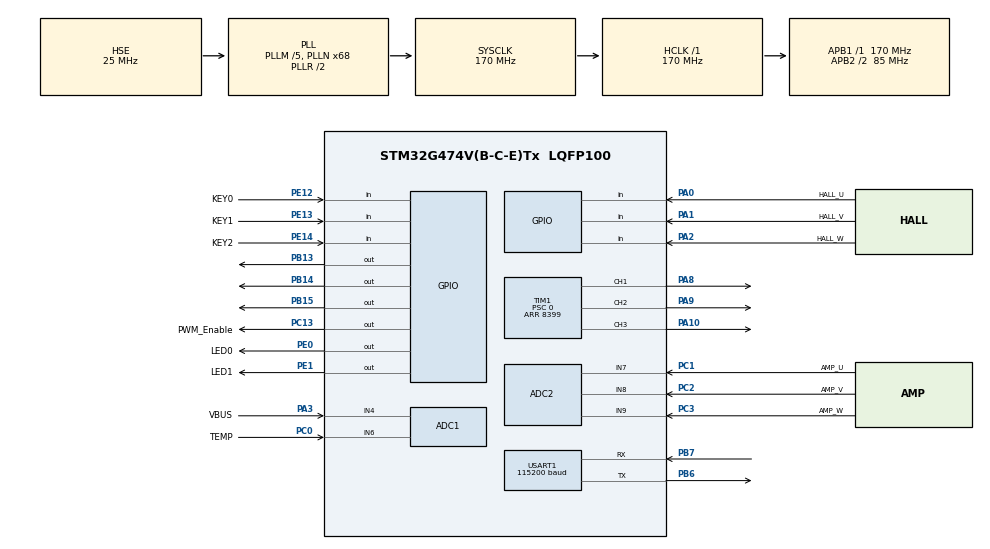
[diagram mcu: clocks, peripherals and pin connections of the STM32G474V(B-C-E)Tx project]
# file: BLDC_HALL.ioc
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ADC1.Channel-2\#ChannelRegularConversion=ADC_CHANNEL_4
ADC1.Channel-3\#ChannelRegularConversion=ADC_CHANNEL_6
ADC1.ContinuousConvMode=ENABLE
ADC1.DMAContinuousRequests=ENABLE
ADC1.EOCSelection=ADC_EOC_SINGLE_CONV
ADC1.EnableInjectedConversion=DISABLE
ADC1.LowPowerAutoWait=DISABLE
ADC1.Mode=ADC_MODE_INDEPENDENT
ADC1.NbrOfConversion=2
ADC1.NbrOfConversionFlag=1
ADC1.OffsetNumber-2\#ChannelRegularConversion=ADC_OFFSET_NONE
ADC1.OffsetNumber-3\#ChannelRegularConversion=ADC_OFFSET_NONE
ADC1.Rank-2\#ChannelRegularConversion=1
ADC1.Rank-3\#ChannelRegularConversion=2
ADC1.SamplingTime-2\#ChannelRegularConversion=ADC_SAMPLETIME_92CYCLES_5
ADC1.SamplingTime-3\#ChannelRegularConversion=ADC_SAMPLETIME_92CYCLES_5
ADC1.master=1
ADC2.EnableAnalogWatchDog1=false
ADC2.EnableInjectedConversion=ENABLE
ADC2.EnableRegularConversion=DISABLE
ADC2.ExternalTrigInjecConv=ADC_EXTERNALTRIGINJEC_T1_TRGO
ADC2.ExternalTrigInjecConvEdge=ADC_EXTERNALTRIGINJECCONV_EDGE_RISING
ADC2.InjNumberOfConversion=3
ADC2.InjectedChannel-1\#ChannelInjectedConversion=ADC_CHANNEL_7
ADC2.InjectedChannel-2\#ChannelInjectedConversion=ADC_CHANNEL_8
ADC2.InjectedChannel-3\#ChannelInjectedConversion=ADC_CHANNEL_9
ADC2.InjectedConvMode=None
ADC2.InjectedOffsetNumber-1\#ChannelInjectedConversion=ADC_OFFSET_NONE
ADC2.InjectedOffsetNumber-2\#ChannelInjectedConversion=ADC_OFFSET_NONE
ADC2.InjectedOffsetNumber-3\#ChannelInjectedConversion=ADC_OFFSET_NONE
ADC2.InjectedRank-1\#ChannelInjectedConversion=1
ADC2.InjectedRank-2\#ChannelInjectedConversion=2
ADC2.InjectedRank-3\#ChannelInjectedConversion=3
ADC2.InjectedSamplingTime-1\#ChannelInjectedConversion=ADC_SAMPLETIME_24CYCLES_5
ADC2.InjectedSamplingTime-2\#ChannelInjectedConversion=ADC_SAMPLETIME_24CYCLES_5
ADC2.InjectedSamplingTime-3\#ChannelInjectedConversion=ADC_SAMPLETIME_24CYCLES_5
Dma.ADC1.1.Direction=DMA_PERIPH_TO_MEMORY
Dma.ADC1.1.EventEnable=DISABLE
Dma.ADC1.1.Instance=DMA1_Channel2
Dma.ADC1.1.MemDataAlignment=DMA_MDATAALIGN_HALFWORD
Dma.ADC1.1.MemInc=DMA_MINC_ENABLE
Dma.ADC1.1.Mode=DMA_CIRCULAR
Dma.ADC1.1.PeriphDataAlignment=DMA_PDATAALIGN_HALFWORD
Dma.ADC1.1.PeriphInc=DMA_PINC_DISABLE
Dma.ADC1.1.Polarity=HAL_DMAMUX_REQ_GEN_RISING
Dma.ADC1.1.Priority=DMA_PRIORITY_LOW
Dma.ADC1.1.RequestNumber=1
Dma.ADC1.1.SignalID=NONE
Dma.ADC1.1.SyncEnable=DISABLE
Dma.ADC1.1.SyncPolarity=HAL_DMAMUX_SYNC_NO_EVENT
Dma.ADC1.1.SyncRequestNumber=1
Dma.ADC1.1.SyncSignalID=NONE
Dma.Request0=USART1_TX
Dma.Request1=ADC1
Dma.USART1_TX.0.Direction=DMA_MEMORY_TO_PERIPH
Dma.USART1_TX.0.EventEnable=DISABLE
Dma.USART1_TX.0.Instance=DMA1_Channel1
Dma.USART1_TX.0.MemDataAlignment=DMA_MDATAALIGN_BYTE
Dma.USART1_TX.0.MemInc=DMA_MINC_ENABLE
Dma.USART1_TX.0.Mode=DMA_NORMAL
Dma.USART1_TX.0.PeriphDataAlignment=DMA_PDATAALIGN_BYTE
Dma.USART1_TX.0.PeriphInc=DMA_PINC_DISABLE
Dma.USART1_TX.0.Polarity=HAL_DMAMUX_REQ_GEN_RISING
Dma.USART1_TX.0.Priority=DMA_PRIORITY_LOW
Dma.USART1_TX.0.RequestNumber=1
Dma.USART1_TX.0.SignalID=NONE
Dma.USART1_TX.0.SyncEnable=DISABLE
Dma.USART1_TX.0.SyncPolarity=HAL_DMAMUX_SYNC_NO_EVENT
Dma.USART1_TX.0.SyncRequestNumber=1
Dma.USART1_TX.0.SyncSignalID=NONE
Mcu.Family=STM32G4
Mcu.Name=STM32G474V(B-C-E)Tx
Mcu.Package=LQFP100
NVIC.ADC1_2_IRQn=true\:2\:0\:true\:false\:true\:true\:true\:true
NVIC.DMA1_Channel1_IRQn=true\:0\:0\:false\:false\:true\:false\:true\:true
NVIC.DMA1_Channel2_IRQn=true\:0\:0\:false\:false\:true\:false\:true\:true
NVIC.PriorityGroup=NVIC_PRIORITYGROUP_4
NVIC.TIM1_BRK_TIM15_IRQn=true\:0\:0\:false\:false\:true\:true\:true\:true
NVIC.TIM1_UP_TIM16_IRQn=true\:1\:0\:true\:false\:true\:true\:true\:true
NVIC.USART1_IRQn=true\:5\:0\:true\:false\:true\:true\:true\:true
PA0.GPIO_Label=HALL_U
PA0.Signal=GPIO_Input
PA1.GPIO_Label=HALL_V
PA1.Signal=GPIO_Input
PA10.Signal=S_TIM1_CH3
PA13.Mode=Serial_Wire
PA13.Signal=SYS_JTMS-SWDIO
PA14.Mode=Serial_Wire
PA14.Signal=SYS_JTCK-SWCLK
PA2.GPIO_Label=HALL_W
PA2.Signal=GPIO_Input
PA3.GPIO_Label=VBUS
PA3.Mode=IN4-Single-Ended
PA3.Signal=ADC1_IN4
PA8.Signal=S_TIM1_CH1
PA9.Signal=S_TIM1_CH2
PB13.GPIO_Speed=GPIO_SPEED_FREQ_HIGH
PB13.PinState=GPIO_PIN_RESET
PB13.Signal=GPIO_Output
PB14.GPIO_Speed=GPIO_SPEED_FREQ_HIGH
PB14.PinState=GPIO_PIN_RESET
PB14.Signal=GPIO_Output
PB15.GPIO_Speed=GPIO_SPEED_FREQ_HIGH
PB15.PinState=GPIO_PIN_RESET
PB15.Signal=GPIO_Output
PB6.GPIO_FM6=__NULL
PB6.GPIO_Speed=GPIO_SPEED_FREQ_HIGH
PB6.Mode=Asynchronous
PB6.Signal=USART1_TX
PB7.GPIO_FM7=__NULL
PB7.GPIO_Speed=GPIO_SPEED_FREQ_HIGH
PB7.Mode=Asynchronous
PB7.Signal=USART1_RX
PC0.GPIO_Label=TEMP
PC0.Signal=SharedAnalog_PC0
PC1.GPIO_Label=AMP_U
PC1.Mode=IN7-Single-Ended
PC1.Signal=ADC2_IN7
PC13.GPIO_Label=PWM_Enable
PC13.PinState=GPIO_PIN_RESET
PC13.Signal=GPIO_Output
PC2.GPIO_Label=AMP_V
PC2.Mode=IN8-Single-Ended
PC2.Signal=ADC2_IN8
PC3.GPIO_Label=AMP_W
PC3.Mode=IN9-Single-Ended
PC3.Signal=ADC2_IN9
PE0.GPIO_Label=LED0
PE0.PinState=GPIO_PIN_SET
PE0.Signal=GPIO_Output
PE1.GPIO_Label=LED1
PE1.PinState=GPIO_PIN_SET
PE1.Signal=GPIO_Output
PE12.GPIO_Label=KEY0
PE12.GPIO_PuPd=GPIO_PULLUP
PE12.Signal=GPIO_Input
PE13.GPIO_Label=KEY1
PE13.GPIO_PuPd=GPIO_PULLUP
PE13.Signal=GPIO_Input
PE14.GPIO_Label=KEY2
PE14.GPIO_PuPd=GPIO_PULLUP
PE14.Signal=GPIO_Input
PF0-OSC_IN.Mode=HSE-External-Oscillator
PF0-OSC_IN.Signal=RCC_OSC_IN
PF1-OSC_OUT.Mode=HSE-External-Oscillator
PF1-OSC_OUT.Signal=RCC_OSC_OUT
ProjectManager.HeapSize=0x200
ProjectManager.StackSize=0x400
ProjectManager.TargetToolchain=MDK-ARM V5.32
RCC.ADC12Freq_Value=170000000
RCC.ADC345Freq_Value=170000000
RCC.AHBFreq_Value=170000000
RCC.APB1Freq_Value=170000000
RCC.APB1TimFreq_Value=170000000
RCC.APB2CLKDivider=RCC_HCLK_DIV2
RCC.APB2Freq_Value=85000000
RCC.APB2TimFreq_Value=170000000
RCC.CortexFreq_Value=170000000
RCC.EXTERNAL_CLOCK_VALUE=12288000
RCC.HCLKFreq_Value=170000000
RCC.HSE_VALUE=25000000
RCC.HSI48_VALUE=48000000
RCC.HSI_VALUE=16000000
RCC.LSE_VALUE=32768
RCC.PLLM=RCC_PLLM_DIV5
RCC.PLLN=68
RCC.PLLSourceVirtual=RCC_PLLSOURCE_HSE
RCC.SYSCLKFreq_VALUE=170000000
RCC.SYSCLKSource=RCC_SYSCLKSOURCE_PLLCLK
RCC.USART1CLockSelection=RCC_USART1CLKSOURCE_HSI
RCC.USBFreq_Value=170000000
RCC.VCOOutputFreq_Value=340000000
SH.S_TIM1_CH1.0=TIM1_CH1,PWM Generation1 CH1
SH.S_TIM1_CH2.0=TIM1_CH2,PWM Generation2 CH2
SH.S_TIM1_CH3.0=TIM1_CH3,PWM Generation3 CH3
SH.SharedAnalog_PC0.0=ADC2_IN6
SH.SharedAnalog_PC0.1=ADC1_IN6,IN6-Single-Ended
TIM1.AutoReloadPreload=TIM_AUTORELOAD_PRELOAD_ENABLE
TIM1.BreakFilter=8
TIM1.BreakPolarity=TIM_BREAKPOLARITY_LOW
TIM1.Channel-PWM\ Generation1\ CH1=TIM_CHANNEL_1
TIM1.Channel-PWM\ Generation2\ CH2=TIM_CHANNEL_2
TIM1.Channel-PWM\ Generation3\ CH3=TIM_CHANNEL_3
TIM1.Channel-PWM\ Generation4\ No\ Output=TIM_CHANNEL_4
TIM1.CounterMode=TIM_COUNTERMODE_CENTERALIGNED1
TIM1.PeriodNoDither=8399
TIM1.Prescaler=0
TIM1.TIM_MasterOutputTrigger=TIM_TRGO_OC4REF
TIM1.TIM_MasterOutputTrigger2=TIM_TRGO2_RESET
TIM1.TIM_MasterSlaveMode=TIM_MASTERSLAVEMODE_ENABLE
TIM5.AutoReloadPreload=TIM_AUTORELOAD_PRELOAD_ENABLE
TIM5.Prescaler=1679
USART1.BaudRate=115200
USART1.VirtualMode-Asynchronous=VM_ASYNC
VP_SYS_VS_DBSignals.Mode=DisableDeadBatterySignals
VP_TIM1_VS_ClockSourceINT.Mode=Internal
VP_TIM1_VS_no_output4.Mode=PWM Generation4 No Output
VP_TIM5_VS_ClockSourceINT.Mode=Internal
board=custom

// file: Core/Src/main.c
/* USER CODE BEGIN Header */
/**
  ******************************************************************************
  * @file           : main.c
  * @brief          : Main program body
  ******************************************************************************
  * @attention
  *
  * Copyright (c) 2026 STMicroelectronics.
  * All rights reserved.
  *
  * This software is licensed under terms that can be found in the LICENSE file
  * in the root directory of this software component.
  * If no LICENSE file comes with this software, it is provided AS-IS.
  *
  ******************************************************************************
  */
/* USER CODE END Header */
#include "main.h"
#include "adc.h"
#include "dma.h"
#include "tim.h"
#include "usart.h"
#include "gpio.h"

/* USER CODE BEGIN Includes */
#include "test.h"
/* USER CODE END Includes */

void SystemClock_Config(void);

int main(void)
{

  /* MCU Configuration--------------------------------------------------------*/

  /* Reset of all peripherals, Initializes the Flash interface and the Systick. */
  HAL_Init();

  /* Configure the system clock */
  SystemClock_Config();

  /* Initialize all configured peripherals */
  MX_GPIO_Init();
  MX_DMA_Init();
  MX_TIM1_Init();
  MX_USART1_UART_Init();
  MX_ADC1_Init();
  MX_ADC2_Init();
  MX_TIM5_Init();
  /* USER CODE BEGIN 2 */

  Test_Init();
  /* USER CODE END 2 */

  /* Infinite loop */
  while (1)
  {

    /* USER CODE BEGIN 3 */
   Test_Loop();
  }
  /* USER CODE END 3 */
}

void SystemClock_Config(void)
{
  RCC_OscInitTypeDef RCC_OscInitStruct = {0};
  RCC_ClkInitTypeDef RCC_ClkInitStruct = {0};

  /** Configure the main internal regulator output voltage
  */
  HAL_PWREx_ControlVoltageScaling(PWR_REGULATOR_VOLTAGE_SCALE1_BOOST);

  /** Initializes the RCC Oscillators according to the specified parameters
  * in the RCC_OscInitTypeDef structure.
  */
  RCC_OscInitStruct.OscillatorType = RCC_OSCILLATORTYPE_HSI|RCC_OSCILLATORTYPE_HSE;
  RCC_OscInitStruct.HSEState = RCC_HSE_ON;
  RCC_OscInitStruct.HSIState = RCC_HSI_ON;
  RCC_OscInitStruct.HSICalibrationValue = RCC_HSICALIBRATION_DEFAULT;
  RCC_OscInitStruct.PLL.PLLState = RCC_PLL_ON;
  RCC_OscInitStruct.PLL.PLLSource = RCC_PLLSOURCE_HSE;
  RCC_OscInitStruct.PLL.PLLM = RCC_PLLM_DIV5;
  RCC_OscInitStruct.PLL.PLLN = 68;
  RCC_OscInitStruct.PLL.PLLP = RCC_PLLP_DIV2;
  RCC_OscInitStruct.PLL.PLLQ = RCC_PLLQ_DIV2;
  RCC_OscInitStruct.PLL.PLLR = RCC_PLLR_DIV2;
  if (HAL_RCC_OscConfig(&RCC_OscInitStruct) != HAL_OK)
  {
    Error_Handler();
  }

  /** Initializes the CPU, AHB and APB buses clocks
  */
  RCC_ClkInitStruct.ClockType = RCC_CLOCKTYPE_HCLK|RCC_CLOCKTYPE_SYSCLK
                              |RCC_CLOCKTYPE_PCLK1|RCC_CLOCKTYPE_PCLK2;
  RCC_ClkInitStruct.SYSCLKSource = RCC_SYSCLKSOURCE_PLLCLK;
  RCC_ClkInitStruct.AHBCLKDivider = RCC_SYSCLK_DIV1;
  RCC_ClkInitStruct.APB1CLKDivider = RCC_HCLK_DIV1;
  RCC_ClkInitStruct.APB2CLKDivider = RCC_HCLK_DIV2;

  if (HAL_RCC_ClockConfig(&RCC_ClkInitStruct, FLASH_LATENCY_4) != HAL_OK)
  {
    Error_Handler();
  }
}

void Error_Handler(void)
{
  __disable_irq();
  while (1)
  {
  }
}
